# ESP32 register map
Vendor: ESPRESSIF SYSTEMS (SHANGHAI) CO., LTD.; Series: ESP32 Series; File version: 17
CPU: Xtensa LX6 r0p0, little endian, no MPU, FPU, 0 interrupt priority bits
Address unit: 32 bits
Registers are 32-bit, read-write, reset 0x0 unless marked. A register's access mark holds for its fields unless they carry their own. Offsets are from the block's base; [hi:lo] are bit positions; {n}, {i} and the like mark numbered series; 'fields as' and 'values as' point back to an identical list.

## RTC_IO — Low-power Input/Output
Base 0x3FF48400
0x00 OUT
  [31:14] DATA — GPIO0~17 output value
0x04 OUT_W1TS wo
  [31:14] OUT_DATA_W1TS — GPIO0~17 output value write 1 to set
0x08 OUT_W1TC wo
  [31:14] OUT_DATA_W1TC — GPIO0~17 output value write 1 to clear
0x0C ENABLE
  [31:14] ENABLE — GPIO0~17 output enable
0x10 ENABLE_W1TS wo
  [31:14] ENABLE_W1TS — GPIO0~17 output enable write 1 to set
0x14 ENABLE_W1TC wo
  [31:14] ENABLE_W1TC — GPIO0~17 output enable write 1 to clear
0x18 STATUS
  [31:14] INT — GPIO0~17 interrupt status
0x1C STATUS_W1TS wo
  [31:14] STATUS_INT_W1TS — GPIO0~17 interrupt status write 1 to set
0x20 STATUS_W1TC wo
  [31:14] STATUS_INT_W1TC — GPIO0~17 interrupt status write 1 to clear
0x24 IN ro
  [31:14] NEXT — GPIO0~17 input value
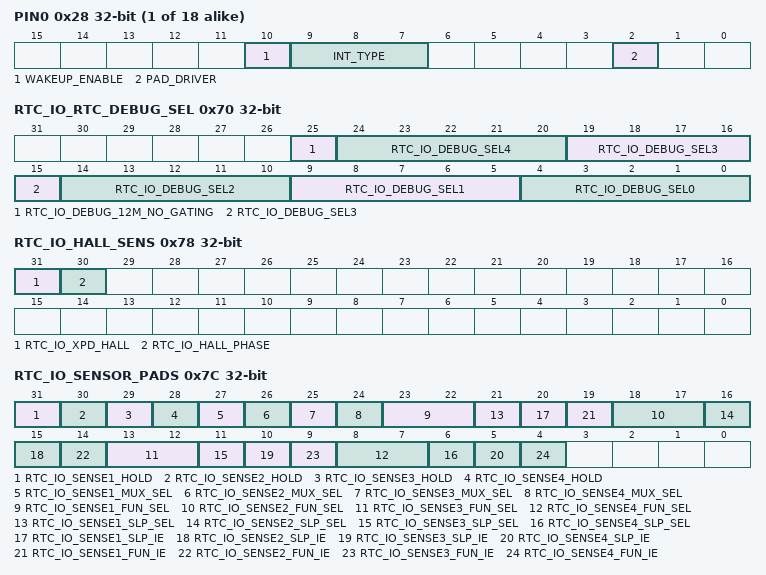
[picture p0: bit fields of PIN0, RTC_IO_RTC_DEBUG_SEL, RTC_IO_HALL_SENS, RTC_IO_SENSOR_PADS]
{0x28+4i} PIN{i} (i=0..17)
  [10] WAKEUP_ENABLE — GPIO wake up enable only available in light sleep
  [9:7] INT_TYPE — if set to 0: GPIO interrupt disable if set to 1: rising edge trigger if set to 2: falling edge trigger if set to 3: any edge trigger if set to 4: low level trigger if set to 5: high level trigger
  [2] PAD_DRIVER — if set to 0: normal output if set to 1: open drain
0x70 RTC_IO_RTC_DEBUG_SEL
  [25] RTC_IO_DEBUG_12M_NO_GATING, [5n+4:5n] RTC_IO_DEBUG_SEL{n} (n=0..4)
0x74 RTC_IO_DIG_PAD_HOLD
  [31:0] RTC_IO_DIG_PAD_HOLD — select the digital pad hold value.
0x78 RTC_IO_HALL_SENS
  [31] RTC_IO_XPD_HALL — Power on hall sensor and connect to VP and VN
  [30] RTC_IO_HALL_PHASE — Reverse phase of hall sensor
0x7C RTC_IO_SENSOR_PADS
  [32-n] RTC_IO_SENSE{n}_HOLD (n=1..4) — hold the current value of the output when setting the hold to Ò1Ó
  [28-n] RTC_IO_SENSE{n}_MUX_SEL (n=1..4) — Ò1Ó select the digital function Ó0Óslection the rtc function
  [28-5n:27-5n] RTC_IO_SENSE{n}_FUN_SEL (n=1..4) — the functional selection signal of the pad
  [26-5n] RTC_IO_SENSE{n}_SLP_SEL (n=1..4) — the sleep status selection signal of the pad
  [25-5n] RTC_IO_SENSE{n}_SLP_IE (n=1..4) — the input enable of the pad in sleep status
  [24-5n] RTC_IO_SENSE{n}_FUN_IE (n=1..4) — the input enable of the pad
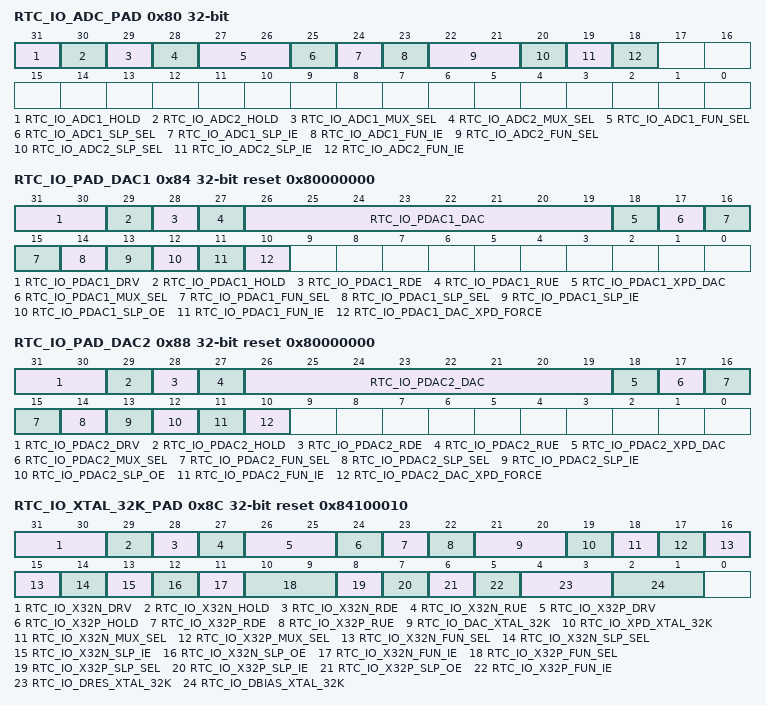
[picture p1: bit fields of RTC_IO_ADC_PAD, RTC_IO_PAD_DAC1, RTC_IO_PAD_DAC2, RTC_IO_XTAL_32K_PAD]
0x80 RTC_IO_ADC_PAD
  [31] RTC_IO_ADC1_HOLD — hold the current value of the output when setting the hold to Ò1Ó
  [30] RTC_IO_ADC2_HOLD — hold the current value of the output when setting the hold to Ò1Ó
  [29] RTC_IO_ADC1_MUX_SEL — Ò1Ó select the digital function Ó0Óslection the rtc function
  [28] RTC_IO_ADC2_MUX_SEL — Ò1Ó select the digital function Ó0Óslection the rtc function
  [27:26] RTC_IO_ADC1_FUN_SEL — the functional selection signal of the pad
  [25] RTC_IO_ADC1_SLP_SEL — the sleep status selection signal of the pad
  [24] RTC_IO_ADC1_SLP_IE — the input enable of the pad in sleep status
  [23] RTC_IO_ADC1_FUN_IE — the input enable of the pad
  [22:21] RTC_IO_ADC2_FUN_SEL — the functional selection signal of the pad
  [20] RTC_IO_ADC2_SLP_SEL — the sleep status selection signal of the pad
  [19] RTC_IO_ADC2_SLP_IE — the input enable of the pad in sleep status
  [18] RTC_IO_ADC2_FUN_IE — the input enable of the pad
0x84 RTC_IO_PAD_DAC1 reset 0x80000000
  [31:30] RTC_IO_PDAC1_DRV — the driver strength of the pad
  [29] RTC_IO_PDAC1_HOLD — hold the current value of the output when setting the hold to Ò1Ó
  [28] RTC_IO_PDAC1_RDE — the pull down enable of the pad
  [27] RTC_IO_PDAC1_RUE — the pull up enable of the pad
  [26:19] RTC_IO_PDAC1_DAC — PAD DAC1 control code.
  [18] RTC_IO_PDAC1_XPD_DAC — Power on DAC1. Usually we need to tristate PDAC1 if we power on the DAC i.e. IE=0 OE=0 RDE=0 RUE=0
  [17] RTC_IO_PDAC1_MUX_SEL — Ò1Ó select the digital function Ó0Óslection the rtc function
  [16:15] RTC_IO_PDAC1_FUN_SEL — the functional selection signal of the pad
  [14] RTC_IO_PDAC1_SLP_SEL — the sleep status selection signal of the pad
  [13] RTC_IO_PDAC1_SLP_IE — the input enable of the pad in sleep status
  [12] RTC_IO_PDAC1_SLP_OE — the output enable of the pad in sleep status
  [11] RTC_IO_PDAC1_FUN_IE — the input enable of the pad
  [10] RTC_IO_PDAC1_DAC_XPD_FORCE — Power on DAC1. Usually we need to tristate PDAC1 if we power on the DAC i.e. IE=0 OE=0 RDE=0 RUE=0
0x88 RTC_IO_PAD_DAC2 reset 0x80000000
  [31:30] RTC_IO_PDAC2_DRV — the driver strength of the pad
  [29] RTC_IO_PDAC2_HOLD — hold the current value of the output when setting the hold to Ò1Ó
  [28] RTC_IO_PDAC2_RDE — the pull down enable of the pad
  [27] RTC_IO_PDAC2_RUE — the pull up enable of the pad
  [26:19] RTC_IO_PDAC2_DAC — PAD DAC2 control code.
  [18] RTC_IO_PDAC2_XPD_DAC — Power on DAC2. Usually we need to tristate PDAC1 if we power on the DAC i.e. IE=0 OE=0 RDE=0 RUE=0
  [17] RTC_IO_PDAC2_MUX_SEL — Ò1Ó select the digital function Ó0Óslection the rtc function
  [16:15] RTC_IO_PDAC2_FUN_SEL — the functional selection signal of the pad
  [14] RTC_IO_PDAC2_SLP_SEL — the sleep status selection signal of the pad
  [13] RTC_IO_PDAC2_SLP_IE — the input enable of the pad in sleep status
  [12] RTC_IO_PDAC2_SLP_OE — the output enable of the pad in sleep status
  [11] RTC_IO_PDAC2_FUN_IE — the input enable of the pad
  [10] RTC_IO_PDAC2_DAC_XPD_FORCE — Power on DAC2. Usually we need to tristate PDAC2 if we power on the DAC i.e. IE=0 OE=0 RDE=0 RUE=0
0x8C RTC_IO_XTAL_32K_PAD reset 0x84100010
  [31:30] RTC_IO_X32N_DRV — the driver strength of the pad
  [29] RTC_IO_X32N_HOLD — hold the current value of the output when setting the hold to Ò1Ó
  [28] RTC_IO_X32N_RDE — the pull down enable of the pad
  [27] RTC_IO_X32N_RUE — the pull up enable of the pad
  [26:25] RTC_IO_X32P_DRV — the driver strength of the pad
  [24] RTC_IO_X32P_HOLD — hold the current value of the output when setting the hold to Ò1Ó
  [23] RTC_IO_X32P_RDE — the pull down enable of the pad
  [22] RTC_IO_X32P_RUE — the pull up enable of the pad
  [21:20] RTC_IO_DAC_XTAL_32K — 32K XTAL bias current DAC.
  [19] RTC_IO_XPD_XTAL_32K — Power up 32kHz crystal oscillator
  [18] RTC_IO_X32N_MUX_SEL — Ò1Ó select the digital function Ó0Óslection the rtc function
  [17] RTC_IO_X32P_MUX_SEL — Ò1Ó select the digital function Ó0Óslection the rtc function
  [16:15] RTC_IO_X32N_FUN_SEL — the functional selection signal of the pad
  [14] RTC_IO_X32N_SLP_SEL — the sleep status selection signal of the pad
  [13] RTC_IO_X32N_SLP_IE — the input enable of the pad in sleep status
  [12] RTC_IO_X32N_SLP_OE — the output enable of the pad in sleep status
  [11] RTC_IO_X32N_FUN_IE — the input enable of the pad
  [10:9] RTC_IO_X32P_FUN_SEL — the functional selection signal of the pad
  [8] RTC_IO_X32P_SLP_SEL — the sleep status selection signal of the pad
  [7] RTC_IO_X32P_SLP_IE — the input enable of the pad in sleep status
  [6] RTC_IO_X32P_SLP_OE — the output enable of the pad in sleep status
  [5] RTC_IO_X32P_FUN_IE — the input enable of the pad
  [4:3] RTC_IO_DRES_XTAL_32K — 32K XTAL resistor bias control.
  [2:1] RTC_IO_DBIAS_XTAL_32K — 32K XTAL self-bias reference control.
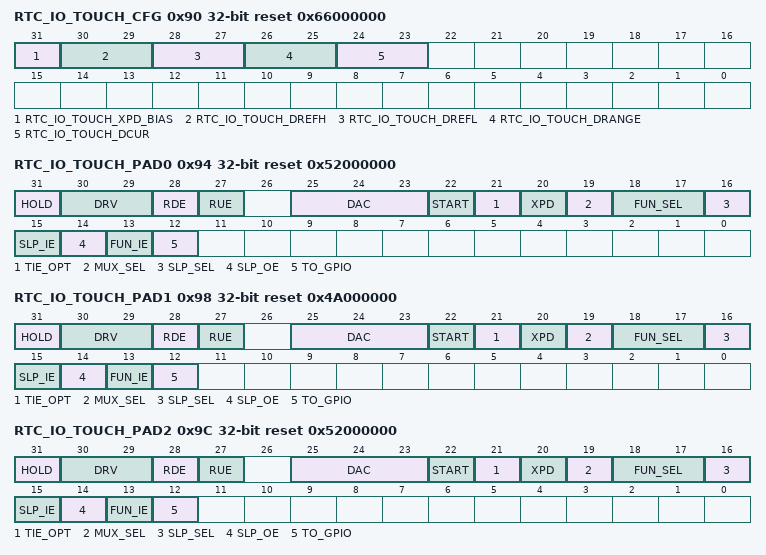
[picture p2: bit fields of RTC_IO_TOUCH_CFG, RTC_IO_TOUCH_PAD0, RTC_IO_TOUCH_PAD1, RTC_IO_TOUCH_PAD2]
0x90 RTC_IO_TOUCH_CFG reset 0x66000000
  [31] RTC_IO_TOUCH_XPD_BIAS — touch sensor bias power on.
  [30:29] RTC_IO_TOUCH_DREFH — touch sensor saw wave top voltage.
  [28:27] RTC_IO_TOUCH_DREFL — touch sensor saw wave bottom voltage.
  [26:25] RTC_IO_TOUCH_DRANGE — touch sensor saw wave voltage range.
  [24:23] RTC_IO_TOUCH_DCUR — touch sensor bias current. Should have option to tie with BIAS_SLEEP(When BIAS_SLEEP this setting is available
0x94 RTC_IO_TOUCH_PAD0 reset 0x52000000
  [31] HOLD — hold the current value of the output when setting the hold to Ò1Ó
  [30:29] DRV — the driver strength of the pad
  [28] RDE — the pull down enable of the pad
  [27] RUE — the pull up enable of the pad
  [25:23] DAC — touch sensor slope control. 3-bit for each touch panel default 100.
  [22] START — start touch sensor.
  [21] TIE_OPT — default touch sensor tie option. 0: tie low 1: tie high.
  [20] XPD — touch sensor power on.
  [19] MUX_SEL — Ò1Ó select the digital function Ó0Óslection the rtc function
  [18:17] FUN_SEL — the functional selection signal of the pad
  [16] SLP_SEL — the sleep status selection signal of the pad
  [15] SLP_IE — the input enable of the pad in sleep status
  [14] SLP_OE — the output enable of the pad in sleep status
  [13] FUN_IE — the input enable of the pad
  [12] TO_GPIO — connect the rtc pad input to digital pad input Ó0Ó is availbale GPIO4
0x98 RTC_IO_TOUCH_PAD1 reset 0x4A000000
  [31] HOLD
  [30:29] DRV — the driver strength of the pad
  [28] RDE — the pull down enable of the pad
  [27] RUE — the pull up enable of the pad
  [25:23] DAC — touch sensor slope control. 3-bit for each touch panel default 100.
  [22] START — start touch sensor.
  [21] TIE_OPT — default touch sensor tie option. 0: tie low 1: tie high.
  [20] XPD — touch sensor power on.
  [19] MUX_SEL — Ò1Ó select the digital function Ó0Óslection the rtc function
  [18:17] FUN_SEL — the functional selection signal of the pad
  [16] SLP_SEL — the sleep status selection signal of the pad
  [15] SLP_IE — the input enable of the pad in sleep status
  [14] SLP_OE — the output enable of the pad in sleep status
  [13] FUN_IE — the input enable of the pad
  [12] TO_GPIO — connect the rtc pad input to digital pad input Ó0Ó is availbale.GPIO0
0x9C RTC_IO_TOUCH_PAD2 reset 0x52000000
  [31] HOLD — hold the current value of the output when setting the hold to Ò1Ó
  [30:29] DRV — the driver strength of the pad
  [28] RDE — the pull down enable of the pad
  [27] RUE — the pull up enable of the pad
  [25:23] DAC — touch sensor slope control. 3-bit for each touch panel default 100.
  [22] START — start touch sensor.
  [21] TIE_OPT — default touch sensor tie option. 0: tie low 1: tie high.
  [20] XPD — touch sensor power on.
  [19] MUX_SEL — Ò1Ó select the digital function Ó0Óslection the rtc function
  [18:17] FUN_SEL — the functional selection signal of the pad
  [16] SLP_SEL — the sleep status selection signal of the pad
  [15] SLP_IE — the input enable of the pad in sleep status
  [14] SLP_OE — the output enable of the pad in sleep status
  [13] FUN_IE — the input enable of the pad
  [12] TO_GPIO — connect the rtc pad input to digital pad input Ó0Ó is availbale.GPIO2
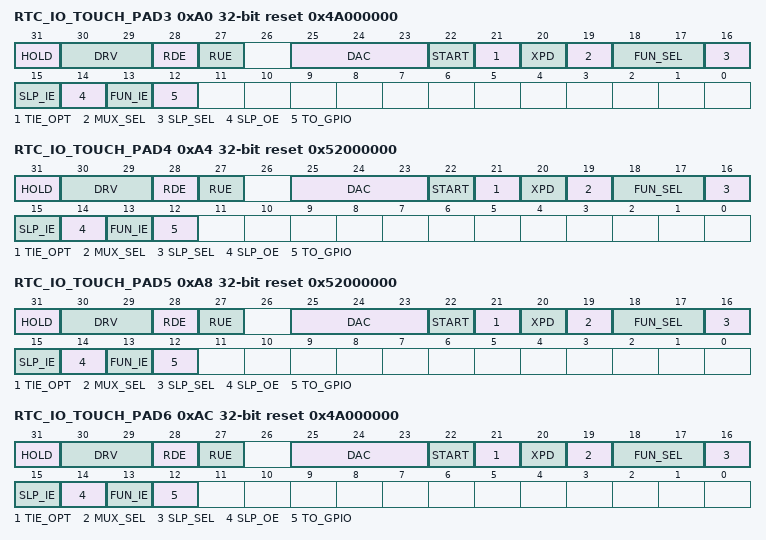
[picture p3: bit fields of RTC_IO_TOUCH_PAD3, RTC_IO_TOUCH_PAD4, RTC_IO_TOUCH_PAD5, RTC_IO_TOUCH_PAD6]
0xA0 RTC_IO_TOUCH_PAD3 reset 0x4A000000
  [31] HOLD — hold the current value of the output when setting the hold to Ò1Ó
  [30:29] DRV — the driver strength of the pad
  [28] RDE — the pull down enable of the pad
  [27] RUE — the pull up enable of the pad
  [25:23] DAC — touch sensor slope control. 3-bit for each touch panel default 100.
  [22] START — start touch sensor.
  [21] TIE_OPT — default touch sensor tie option. 0: tie low 1: tie high.
  [20] XPD — touch sensor power on.
  [19] MUX_SEL — Ò1Ó select the digital function Ó0Óslection the rtc function
  [18:17] FUN_SEL — the functional selection signal of the pad
  [16] SLP_SEL — the sleep status selection signal of the pad
  [15] SLP_IE — the input enable of the pad in sleep status
  [14] SLP_OE — the output enable of the pad in sleep status
  [13] FUN_IE — the input enable of the pad
  [12] TO_GPIO — connect the rtc pad input to digital pad input Ó0Ó is availbale.MTDO
0xA4 RTC_IO_TOUCH_PAD4 reset 0x52000000
  [31] HOLD — hold the current value of the output when setting the hold to Ò1Ó
  [30:29] DRV — the driver strength of the pad
  [28] RDE — the pull down enable of the pad
  [27] RUE — the pull up enable of the pad
  [25:23] DAC — touch sensor slope control. 3-bit for each touch panel default 100.
  [22] START — start touch sensor.
  [21] TIE_OPT — default touch sensor tie option. 0: tie low 1: tie high.
  [20] XPD — touch sensor power on.
  [19] MUX_SEL — Ò1Ó select the digital function Ó0Óslection the rtc function
  [18:17] FUN_SEL — the functional selection signal of the pad
  [16] SLP_SEL — the sleep status selection signal of the pad
  [15] SLP_IE — the input enable of the pad in sleep status
  [14] SLP_OE — the output enable of the pad in sleep status
  [13] FUN_IE — the input enable of the pad
  [12] TO_GPIO — connect the rtc pad input to digital pad input Ó0Ó is availbale.MTCK
0xA8 RTC_IO_TOUCH_PAD5 reset 0x52000000
  [31] HOLD — hold the current value of the output when setting the hold to Ò1Ó
  [30:29] DRV — the driver strength of the pad
  [28] RDE — the pull down enable of the pad
  [27] RUE — the pull up enable of the pad
  [25:23] DAC — touch sensor slope control. 3-bit for each touch panel default 100.
  [22] START — start touch sensor.
  [21] TIE_OPT — default touch sensor tie option. 0: tie low 1: tie high.
  [20] XPD — touch sensor power on.
  [19] MUX_SEL — Ò1Ó select the digital function Ó0Óslection the rtc function
  [18:17] FUN_SEL — the functional selection signal of the pad
  [16] SLP_SEL — the sleep status selection signal of the pad
  [15] SLP_IE — the input enable of the pad in sleep status
  [14] SLP_OE — the output enable of the pad in sleep status
  [13] FUN_IE — the input enable of the pad
  [12] TO_GPIO — connect the rtc pad input to digital pad input Ó0Ó is availbale.MTDI
0xAC RTC_IO_TOUCH_PAD6 reset 0x4A000000
  [31] HOLD — hold the current value of the output when setting the hold to Ò1Ó
  [30:29] DRV — the driver strength of the pad
  [28] RDE — the pull down enable of the pad
  [27] RUE — the pull up enable of the pad
  [25:23] DAC — touch sensor slope control. 3-bit for each touch panel default 100.
  [22] START — start touch sensor.
  [21] TIE_OPT — default touch sensor tie option. 0: tie low 1: tie high.
  [20] XPD — touch sensor power on.
  [19] MUX_SEL — Ò1Ó select the digital function Ó0Óslection the rtc function
  [18:17] FUN_SEL — the functional selection signal of the pad
  [16] SLP_SEL — the sleep status selection signal of the pad
  [15] SLP_IE — the input enable of the pad in sleep status
  [14] SLP_OE — the output enable of the pad in sleep status
  [13] FUN_IE — the input enable of the pad
  [12] TO_GPIO — connect the rtc pad input to digital pad input Ó0Ó is availbale.MTMS
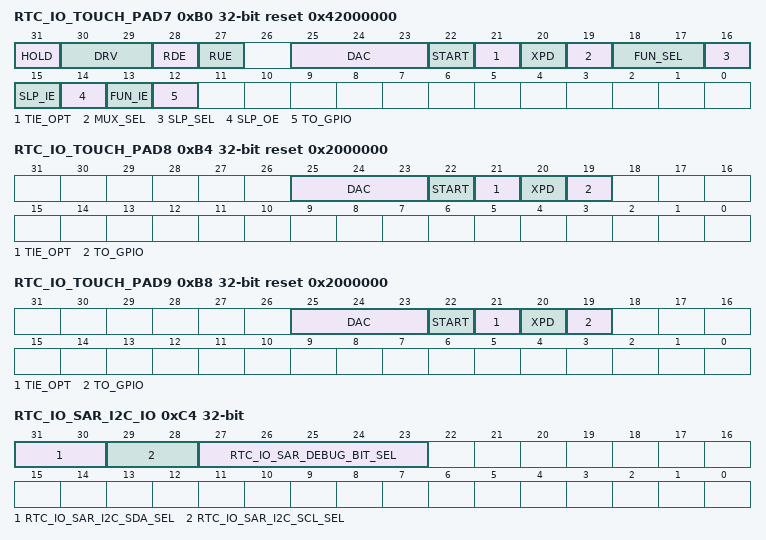
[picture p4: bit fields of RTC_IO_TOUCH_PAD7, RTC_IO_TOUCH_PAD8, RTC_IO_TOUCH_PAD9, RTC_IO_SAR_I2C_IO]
0xB0 RTC_IO_TOUCH_PAD7 reset 0x42000000
  [31] HOLD — hold the current value of the output when setting the hold to Ò1Ó
  [30:29] DRV — the driver strength of the pad
  [28] RDE — the pull down enable of the pad
  [27] RUE — the pull up enable of the pad
  [25:23] DAC — touch sensor slope control. 3-bit for each touch panel default 100.
  [22] START — start touch sensor.
  [21] TIE_OPT — default touch sensor tie option. 0: tie low 1: tie high.
  [20] XPD — touch sensor power on.
  [19] MUX_SEL — Ò1Ó select the digital function Ó0Óslection the rtc function
  [18:17] FUN_SEL — the functional selection signal of the pad
  [16] SLP_SEL — the sleep status selection signal of the pad
  [15] SLP_IE — the input enable of the pad in sleep status
  [14] SLP_OE — the output enable of the pad in sleep status
  [13] FUN_IE — the input enable of the pad
  [12] TO_GPIO — connect the rtc pad input to digital pad input Ó0Ó is availbale.GPIO27
0xB4 RTC_IO_TOUCH_PAD8 reset 0x2000000
  [25:23] DAC — touch sensor slope control. 3-bit for each touch panel default 100.
  [22] START — start touch sensor.
  [21] TIE_OPT — default touch sensor tie option. 0: tie low 1: tie high.
  [20] XPD — touch sensor power on.
  [19] TO_GPIO — connect the rtc pad input to digital pad input Ó0Ó is availbale
0xB8 RTC_IO_TOUCH_PAD9 reset 0x2000000
  fields as RTC_IO_TOUCH_PAD8
0xBC RTC_IO_EXT_WAKEUP0
  [31:27] SEL — select the wakeup source Ó0Ó select GPIO0 Ó1Ó select GPIO2 ...Ò17Ó select GPIO17
0xC0 RTC_IO_XTL_EXT_CTR
  [31:27] SEL — select the external xtl power source Ó0Ó select GPIO0 Ó1Ó select GPIO2 ...Ò17Ó select GPIO17
0xC4 RTC_IO_SAR_I2C_IO
  [31:30] RTC_IO_SAR_I2C_SDA_SEL — Ò0Ó using TOUCH_PAD[1] as i2c sda Ò1Ó using TOUCH_PAD[3] as i2c sda
  [29:28] RTC_IO_SAR_I2C_SCL_SEL — Ò0Ó using TOUCH_PAD[0] as i2c clk Ò1Ó using TOUCH_PAD[2] as i2c clk
  [27:23] RTC_IO_SAR_DEBUG_BIT_SEL
0xC8 RTC_IO_DATE reset 0x1603160
  [27:0] RTC_IO_IO_DATE — date
